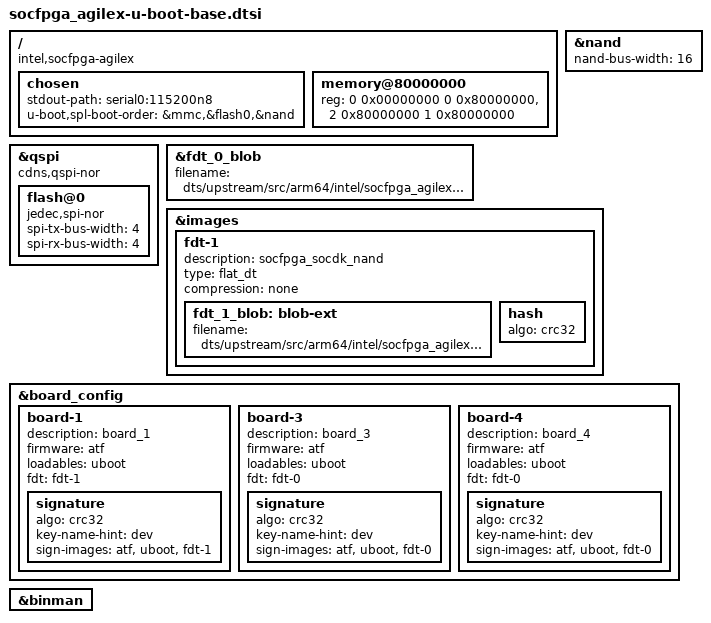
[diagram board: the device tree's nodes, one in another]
// SPDX-License-Identifier: GPL-2.0+
/*
 * U-Boot additions
 *
 * Copyright (C) 2019-2022 Intel Corporation <www.intel.com>
 * Copyright (C) 2025 Altera Corporation <www.altera.com>
 */

#include "socfpga_agilex-u-boot.dtsi"

/{
	compatible = "intel,socfpga-agilex";
	chosen {
		stdout-path = "serial0:115200n8";
		u-boot,spl-boot-order = &mmc,&flash0,&nand;
	};

	memory@80000000 {
		/* 8GB */
		reg = <0 0x00000000 0 0x80000000>,
		      <2 0x80000000 1 0x80000000>;
	};
};

&nand {
	status = "okay";
	nand-bus-width = <16>;
	bootph-all;
};

&qspi {
	compatible = "cdns,qspi-nor";
	status = "okay";
	/delete-property/ clocks;
	flash@0 {
		compatible = "jedec,spi-nor";
		spi-tx-bus-width = <4>;
		spi-rx-bus-width = <4>;
		bootph-all;
		/delete-property/ cdns,read-delay;
	};
};

#if !defined(CONFIG_SOCFPGA_SECURE_VAB_AUTH)
&fdt_0_blob {
	filename = "dts/upstream/src/arm64/intel/socfpga_agilex_socdk.dtb";
};

&images {
	fdt-1 {
		description = "socfpga_socdk_nand";
		type = "flat_dt";
		compression = "none";
		fdt_1_blob: blob-ext {
			filename = "dts/upstream/src/arm64/intel/socfpga_agilex_socdk.dtb";
		};
		hash {
			algo = "crc32";
		};
	};
};

&board_config {
	board-1 {
		description = "board_1";
		firmware = "atf";
		loadables = "uboot";
		fdt = "fdt-1";
		signature {
			algo = "crc32";
			key-name-hint = "dev";
			sign-images = "atf", "uboot", "fdt-1";
		};
	};

	board-3 {
	description = "board_3";
		firmware = "atf";
		loadables = "uboot";
		fdt = "fdt-0";
		signature {
			algo = "crc32";
			key-name-hint = "dev";
			sign-images = "atf", "uboot", "fdt-0";
		};
	};

	board-4 {
		description = "board_4";
		firmware = "atf";
		loadables = "uboot";
		fdt = "fdt-0";
		signature {
			algo = "crc32";
			key-name-hint = "dev";
			sign-images = "atf", "uboot", "fdt-0";
		};
	};
};

&binman {
	/delete-node/ kernel;
};
#endif
